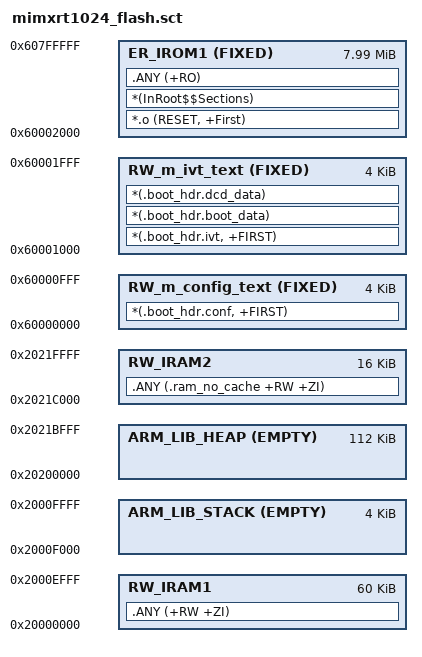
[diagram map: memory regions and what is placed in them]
;******************************************************************
;* i.MX RT1024 linker scatter file (running code from QSPI Flash) *
;******************************************************************

LR_IROM1 0x60000000 0x400000
{
   RW_m_config_text 0x60000000 FIXED 0x1000
   {
      *(.boot_hdr.conf, +FIRST)
   }
   
   RW_m_ivt_text 0x60001000 FIXED 0x1000
   {
      *(.boot_hdr.ivt, +FIRST)
      *(.boot_hdr.boot_data)
      *(.boot_hdr.dcd_data)
   }
   
   ER_IROM1 0x60002000 FIXED 0x7FE000
   {
      *.o (RESET, +First)
      *(InRoot$$Sections)
      .ANY (+RO)
   }
   
   RW_IRAM1 0x20000000 0xF000
   {
      .ANY (+RW +ZI)
   }
   
   ARM_LIB_STACK 0x20010000 EMPTY -0x1000
   {
   }
   
   ARM_LIB_HEAP 0x20200000 EMPTY 0x1C000
   {
   }
   
   RW_IRAM2 0x2021C000 0x4000
   {
      .ANY (.ram_no_cache +RW +ZI)
   }
}
